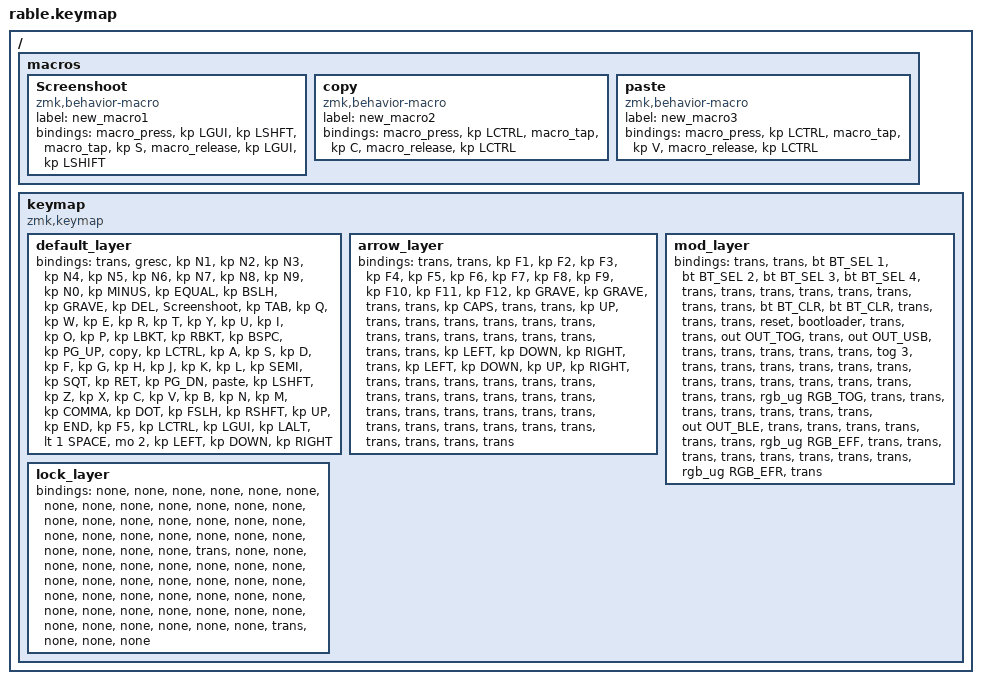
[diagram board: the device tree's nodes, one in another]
/*
 * Copyright (c) 2021 Nick Winans
 *
 * SPDX-License-Identifier: MIT
 */

#include <behaviors.dtsi>
#include <dt-bindings/zmk/keys.h>
#include <dt-bindings/zmk/bt.h>
#include <dt-bindings/zmk/outputs.h>
#include <dt-bindings/zmk/rgb.h>

/ {
    macros {
        Screenshoot: Screenshoot {
            compatible = "zmk,behavior-macro";
            label = "new_macro1";
            #binding-cells = <0>;
            bindings =
                <&macro_press>,
                <&kp LGUI &kp LSHFT>,
                <&macro_tap>,
                <&kp S>,
                <&macro_release>,
                <&kp LGUI &kp LSHIFT>;
        };
        copy: copy {
            compatible = "zmk,behavior-macro";
            label = "new_macro2";
            #binding-cells = <0>;
            bindings =
                <&macro_press>,
                <&kp LCTRL>,
                <&macro_tap>,
                <&kp C>,
                <&macro_release>,
                <&kp LCTRL>;
        };
        paste: paste {
            compatible = "zmk,behavior-macro";
            label = "new_macro3";
            #binding-cells = <0>;
            bindings =
                <&macro_press>,
                <&kp LCTRL>,
                <&macro_tap>,
                <&kp V>,
                <&macro_release>,
                <&kp LCTRL>;
        };
    };

    keymap {
        compatible = "zmk,keymap";

        default_layer {
            bindings = <
 &trans  &gresc  &kp N1  &kp N2  &kp N3  &kp N4  &kp N5  &kp N6  &kp N7  &kp N8  &kp N9  &kp N0  &kp MINUS  &kp EQUAL  &kp BSLH  &kp GRAVE  &kp DEL  &Screenshoot  &kp TAB   &kp Q   &kp W   &kp E   &kp R   &kp T   &kp Y   &kp U   &kp I   &kp O   &kp P  &kp LBKT  &kp RBKT  &kp BSPC  &kp PG_UP   &copy  &kp LCTRL   &kp A   &kp S   &kp D   &kp F   &kp G   &kp H   &kp J   &kp K   &kp L  &kp SEMI  &kp SQT  &kp RET  &kp PG_DN  &paste  &kp LSHFT   &kp Z   &kp X   &kp C   &kp V   &kp B   &kp N   &kp M  &kp COMMA  &kp DOT  &kp FSLH  &kp RSHFT  &kp UP  &kp END  &kp F5  &kp LCTRL  &kp LGUI  &kp LALT  &lt 1 SPACE   &mo 2  &kp LEFT  &kp DOWN  &kp RIGHT
            >;
        };

        arrow_layer {
            bindings = <
 &trans  &trans  &kp F1  &kp F2  &kp F3  &kp F4  &kp F5  &kp F6  &kp F7  &kp F8  &kp F9  &kp F10  &kp F11  &kp F12  &kp GRAVE  &kp GRAVE  &trans  &trans  &kp CAPS  &trans  &trans  &kp UP  &trans  &trans  &trans  &trans  &trans  &trans  &trans  &trans  &trans  &trans  &trans  &trans  &trans  &trans  &kp LEFT  &kp DOWN  &kp RIGHT  &trans  &kp LEFT  &kp DOWN  &kp UP  &kp RIGHT  &trans  &trans  &trans  &trans  &trans  &trans  &trans  &trans  &trans  &trans  &trans  &trans  &trans  &trans  &trans  &trans  &trans  &trans  &trans  &trans  &trans  &trans  &trans  &trans  &trans  &trans  &trans  &trans
            >;
        };

        mod_layer {
            bindings = <
 &trans  &trans  &bt BT_SEL 1  &bt BT_SEL 2  &bt BT_SEL 3  &bt BT_SEL 4  &trans  &trans  &trans  &trans  &trans  &trans  &trans  &trans  &bt BT_CLR  &bt BT_CLR  &trans  &trans  &trans  &reset  &bootloader  &trans  &trans  &out OUT_TOG  &trans  &out OUT_USB  &trans  &trans  &trans  &trans  &trans  &tog 3  &trans  &trans  &trans  &trans  &trans  &trans  &trans  &trans  &trans  &trans  &trans  &trans  &trans  &trans  &rgb_ug RGB_TOG  &trans  &trans  &trans  &trans  &trans  &trans  &trans  &out OUT_BLE  &trans  &trans  &trans  &trans  &trans  &trans  &rgb_ug RGB_EFF  &trans  &trans  &trans  &trans  &trans  &trans  &trans  &trans  &rgb_ug RGB_EFR  &trans
            >;
        };

        lock_layer {
            bindings = <
  &none   &none   &none   &none   &none   &none   &none   &none   &none   &none   &none   &none   &none   &none   &none   &none   &none   &none   &none   &none   &none   &none   &none   &none   &none   &none   &none   &none   &none   &none   &none  &trans   &none   &none   &none   &none   &none   &none   &none   &none   &none   &none   &none   &none   &none   &none   &none   &none   &none   &none   &none   &none   &none   &none   &none   &none   &none   &none   &none   &none   &none   &none   &none   &none   &none   &none   &none   &none  &trans   &none   &none   &none
            >;
        };
    };
};
